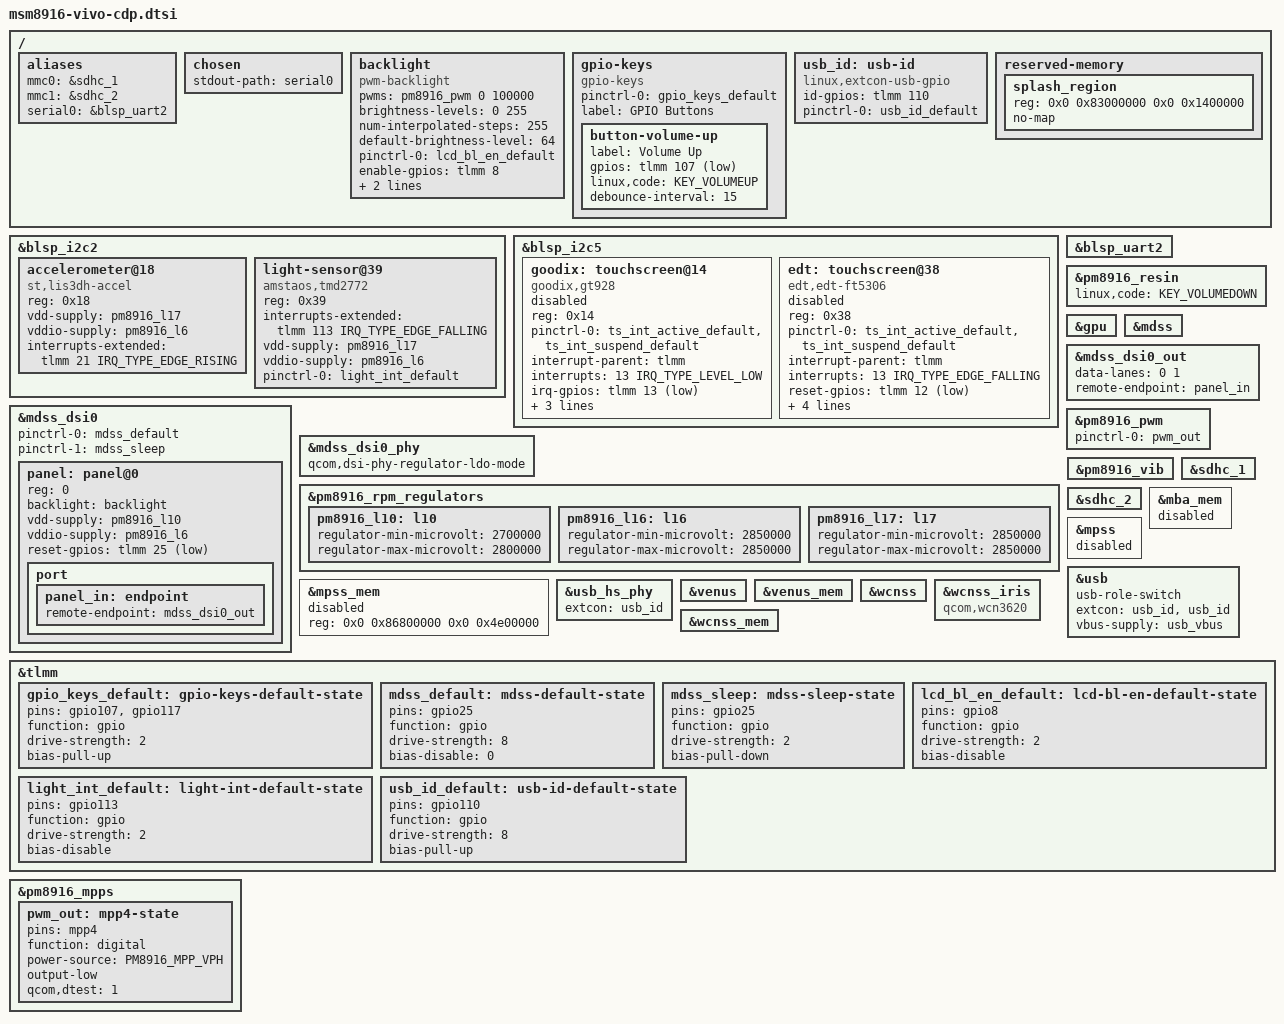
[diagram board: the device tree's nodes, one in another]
// SPDX-License-Identifier: GPL-2.0-only

/dts-v1/;

#include "msm8916-pm8916.dtsi"
#include "msm8916-modem-qdsp6.dtsi"

#include <dt-bindings/gpio/gpio.h>
#include <dt-bindings/input/input.h>
#include <dt-bindings/leds/common.h>
#include <dt-bindings/pinctrl/qcom,pmic-gpio.h>
#include <dt-bindings/pinctrl/qcom,pmic-mpp.h>
#include <dt-bindings/power/summit,smb347-charger.h>


/ {
	aliases {
		mmc0 = &sdhc_1; /* eMMC */
		mmc1 = &sdhc_2; /* SD card */
		serial0 = &blsp_uart2;
	};
	
	chosen {
		stdout-path = "serial0";
	};

	backlight: backlight {
		compatible = "pwm-backlight";
		pwms = <&pm8916_pwm 0 100000>;

		brightness-levels = <0 255>;
		num-interpolated-steps = <255>;
		default-brightness-level = <64>;

		pinctrl-names = "default";
		pinctrl-0 = <&lcd_bl_en_default>;
		enable-gpios = <&tlmm 8 GPIO_ACTIVE_HIGH>;
		post-pwm-on-delay-ms = <10>;
		pwm-off-delay-ms = <10>;
	};

	gpio-keys {
		compatible = "gpio-keys";

		pinctrl-names = "default";
		pinctrl-0 = <&gpio_keys_default>;

		label = "GPIO Buttons";

		button-volume-up {
			label = "Volume Up";
			gpios = <&tlmm 107 GPIO_ACTIVE_LOW>;
			linux,code = <KEY_VOLUMEUP>;
			debounce-interval = <15>;
		};
	};

	usb_id: usb-id {
		compatible = "linux,extcon-usb-gpio";
		id-gpios = <&tlmm 110 GPIO_ACTIVE_HIGH>;
		pinctrl-names = "default";
		pinctrl-0 = <&usb_id_default>;
	};

	reserved-memory{
		splash_region{
			reg=<0x0 0x83000000 0x0 0x1400000>;
			no-map;
		};

	};

	
};

&blsp_i2c2 {
	status = "okay";

	accelerometer@18 {
		compatible = "st,lis3dh-accel";
		reg = <0x18>;
		vdd-supply = <&pm8916_l17>;
		vddio-supply = <&pm8916_l6>;
		interrupts-extended = <&tlmm 21 IRQ_TYPE_EDGE_RISING>;
	};
	
	light-sensor@39 {
		compatible = "amstaos,tmd2772";
		reg = <0x39>;
		interrupts-extended = <&tlmm 113 IRQ_TYPE_EDGE_FALLING>;
		vdd-supply = <&pm8916_l17>;
		vddio-supply = <&pm8916_l6>;
		pinctrl-0 = <&light_int_default>;
		pinctrl-names = "default";
	};

};



&blsp_i2c5 {
	status = "okay";
	
	goodix: touchscreen@14 {
		compatible = "goodix,gt928";
		reg = <0x14>;

		pinctrl-0 =  <&ts_int_active_default &ts_int_suspend_default>;
		pinctrl-names = "default";
		interrupt-parent = <&tlmm>;
		interrupts = <13 IRQ_TYPE_LEVEL_LOW>;
		irq-gpios = <&tlmm 13 GPIO_ACTIVE_LOW>;
		reset-gpios = <&tlmm 12 GPIO_ACTIVE_LOW>;

		AVDD28-supply = <&pm8916_l16>;
		vdd-supply =  <&pm8916_l16>;

		status = "disable";

	};

	
	edt: touchscreen@38 {
		compatible = "edt,edt-ft5306";
		reg = <0x38>;

		pinctrl-0 = <&ts_int_active_default &ts_int_suspend_default>; 
		pinctrl-names = "default";
		interrupt-parent = <&tlmm>;
		interrupts = <13 IRQ_TYPE_EDGE_FALLING>;
		reset-gpios = <&tlmm 12 GPIO_ACTIVE_LOW>;

		vcc-supply = <&pm8916_l16>;
		iovcc-supply = <&pm8916_l6>;
		touchscreen-size-x = <480>;
		touchscreen-size-y = <854>;

		status = "disable";
	};
	
};

&blsp_uart2 {
	status = "okay";
};

&pm8916_resin {
	linux,code = <KEY_VOLUMEDOWN>;
	status = "okay";
};

&gpu {
	status = "okay";
};

&mdss {
	status = "okay";
};

&mdss_dsi0 {
	pinctrl-0 = <&mdss_default>;
	pinctrl-1 = <&mdss_sleep>;
	pinctrl-names = "default", "sleep";

	panel: panel@0 {
	
		reg = <0>;

		backlight = <&backlight>;
		vdd-supply = <&pm8916_l10>;
		vddio-supply = <&pm8916_l6>;

		reset-gpios = <&tlmm 25 GPIO_ACTIVE_LOW>;

		port {
			panel_in: endpoint {
				remote-endpoint = <&mdss_dsi0_out>;
			};
		};
	};
};

&mdss_dsi0_out {
	data-lanes = <0 1>;
	remote-endpoint = <&panel_in>;
};

&mdss_dsi0_phy {
	qcom,dsi-phy-regulator-ldo-mode;
};

&pm8916_pwm {
	status = "okay";
	pinctrl-names = "default";
	pinctrl-0 = <&pwm_out>;
};

&pm8916_rpm_regulators {
	pm8916_l10: l10 {
		regulator-min-microvolt = <2700000>;
		regulator-max-microvolt = <2800000>;
	};

	pm8916_l16: l16 {
		regulator-min-microvolt = <2850000>;
		regulator-max-microvolt = <2850000>;
	};

	pm8916_l17: l17 {
		regulator-min-microvolt = <2850000>;
		regulator-max-microvolt = <2850000>;
	};

};

&pm8916_vib {
	status = "okay";
};

&sdhc_1 {
	status = "okay";
};

&sdhc_2 {
	status = "okay";


};

&mba_mem {
	status = "disable";
};

&mpss {
	status = "disable";

};

&mpss_mem {
	status = "disable";
	reg = <0x0 0x86800000 0x0 0x4e00000>;
};

&usb {
	status = "okay";
	usb-role-switch;
	extcon = <&usb_id>, <&usb_id>;
	vbus-supply = <&usb_vbus>;
};

&usb_hs_phy {
	extcon = <&usb_id>;
};

&venus {
	status = "okay";
};

&venus_mem {
	status = "okay";
};

&wcnss {
	status = "okay";
};

&wcnss_iris {
	compatible = "qcom,wcn3620";
};

&wcnss_mem {
	status = "okay";
};

&tlmm {
	gpio_keys_default: gpio-keys-default-state {
		pins = "gpio107", "gpio117";
		function = "gpio";

		drive-strength = <2>;
		bias-pull-up;
	};

	mdss_default: mdss-default-state {
		pins = "gpio25";
		function = "gpio";
		drive-strength = <8>;
		bias-disable = <0>;
	};

	mdss_sleep: mdss-sleep-state {
		pins = "gpio25";
		function = "gpio";
		drive-strength = <2>;
		bias-pull-down;
	};

	lcd_bl_en_default: lcd-bl-en-default-state {
		pins = "gpio8";
		function = "gpio";

		drive-strength = <2>;
		bias-disable;
	};
	
	light_int_default: light-int-default-state {
		pins = "gpio113";
		function = "gpio";
		drive-strength = <2>;
		bias-disable;
	};
	
	usb_id_default: usb-id-default-state {
		pins = "gpio110";
		function = "gpio";

		drive-strength = <8>;
		bias-pull-up;
	};
};

&pm8916_mpps {
	pwm_out: mpp4-state {
		pins = "mpp4";
		function = "digital";
		power-source = <PM8916_MPP_VPH>;
		output-low;
		qcom,dtest = <1>;
	};
};
